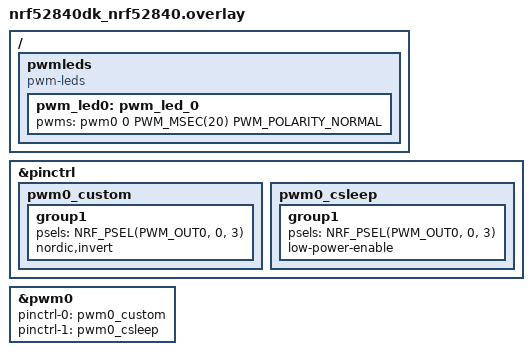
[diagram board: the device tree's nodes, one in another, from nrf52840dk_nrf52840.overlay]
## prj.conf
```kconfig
#Logging configurations
CONFIG_LOG=y
CONFIG_PWM_LOG_LEVEL_DBG=y
CONFIG_LOG_PRINTK=y
CONFIG_LOG_MODE_IMMEDIATE=y
CONFIG_STDOUT_CONSOLE=y
CONFIG_PRINTK=y

#PWM and LED configurations
CONFIG_PWM=y
CONFIG_LED=y
CONFIG_LED_PWM=y

# Step 3.1 - Config for button handler
# Configure buttons and LEDs. CONFIG_GPIO is already enabled through other configs?
CONFIG_DK_LIBRARY=y
```

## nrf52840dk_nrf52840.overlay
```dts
// To get started, press Ctrl+Space to bring up the completion menu and view the available nodes.

// You can also use the buttons in the sidebar to perform actions on nodes.
// Actions currently available include:

// * Enabling / disabling the node
// * Adding the bus to a bus
// * Removing the node
// * Connecting ADC channels

// For more help, browse the DeviceTree documentation at https://docs.zephyrproject.org/latest/guides/dts/index.html
// You can also visit the nRF DeviceTree extension documentation at https://nrfconnect.github.io/vscode-nrf-connect/devicetree/nrfdevicetree.html




/* Step 1.4 - Define pwm0_custom and pwm0_sleep */
&pinctrl {
    pwm0_custom: pwm0_custom {
        group1 {
            psels = <NRF_PSEL(PWM_OUT0, 0, 3)>;
            nordic,invert;
        };
    };

    pwm0_csleep: pwm0_csleep {
        group1 {
            psels = <NRF_PSEL(PWM_OUT0, 0, 3)>;
            low-power-enable;
        };
    };
};
/* Step 1.3 - Add the pwm0 instance */
&pwm0 {
    status = "okay";
    pinctrl-0 = <&pwm0_custom>;
    pinctrl-1 = <&pwm0_csleep>;
    pinctrl-names = "default", "sleep";
};

/* Step 1.2 -  Add a pwm_led instance and change the polarity */
/{
    pwmleds {
        compatible = "pwm-leds";
        pwm_led0: pwm_led_0 {
            pwms = <&pwm0 0 PWM_MSEC(20) PWM_POLARITY_NORMAL>;
        };
    };
};
```

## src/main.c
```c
#include <zephyr/kernel.h>
#include <zephyr/device.h>
#include <zephyr/drivers/pwm.h>
#include <zephyr/logging/log.h>
#include <dk_buttons_and_leds.h>

#define LOG_MODULE_NAME excersize_3
LOG_MODULE_REGISTER(LOG_MODULE_NAME);

static const struct pwm_dt_spec pwm_led0 = PWM_DT_SPEC_GET(DT_ALIAS(pwm_led0));


#define PWM_PERIOD_NS 10000000
#define PWM_DUTY_CYCLE 1400000

/* Step  2.2 - Define minimum and maximum duty cycle */
#define PWM_MIN_DUTY_CYCLE 600000
#define PWM_MAX_DUTY_CYCLE 2000000

/* Step 3 - Create an initializing function to verify that the device is enabled*/ 
int motor_init(void)
{
    int err = 0;
    LOG_INF("Initializing Motor Control");

    if (!device_is_ready(pwm_led0.dev)) {
    LOG_ERR("Error: PWM device %s is not ready",
            pwm_led0.dev->name);
    return -EBUSY;
	}

    err = pwm_set_dt(&pwm_led0, PWM_PERIOD_NS, PWM_DUTY_CYCLE);
    if (err) {
        LOG_ERR("pwm_set_dt returned %d", err);
    }

    return err;
}

/* Step 2.1 - Create a function to set the angle of the motor*/
int set_motor_angle(uint32_t duty_cycle_ns)
{
    int err;
    err = pwm_set_dt(&pwm_led0, PWM_PERIOD_NS, duty_cycle_ns);
    if (err) {
        LOG_ERR("pwm_set_dt_returned %d", err);
    }
 
    return err;
}

/* Step 3.4 - Add button handler callback function */
void button_handler(uint32_t button_state, uint32_t has_changed)
{
    int err = 0;
	int button_pressed = 0;
	if (has_changed & button_state)
	{
		switch (has_changed)
		{
			case DK_BTN1_MSK:
				button_pressed = 1;
                err = set_motor_angle(PWM_MIN_DUTY_CYCLE);
				break;
			case DK_BTN2_MSK:
				button_pressed = 2;
                err = set_motor_angle(PWM_MAX_DUTY_CYCLE);
				break;
			default:
				break;
		}
        LOG_INF("Button %d pressed.", button_pressed);
        if (err) {
            LOG_ERR("couldn't set duty cycle. Err %d", err);
        }
		LOG_INF("Button %d pressed.", button_pressed);
	}
}

/* Step 3.2 - Create a button and led initialization function */
static void configure_dk_buttons_and_leds(void)
{
    int err;

    err = dk_buttons_init(button_handler);
    if (err) {
        LOG_ERR("Couldn't init buttons (err %d)", err);
    }
}


void main(void)
{
    LOG_INF("Starting PWM basic sample \n");
    motor_init();
    /* Step 3.2 - Test your code */
    configure_dk_buttons_and_leds();

    for (;;){

        /* Step 2.3 */
        LOG_INF("Setting motor angle to %d",PWM_MIN_DUTY_CYCLE);
        set_motor_angle(PWM_MIN_DUTY_CYCLE);
        k_sleep(K_SECONDS(5));
        LOG_INF("Setting motor angle to %d",PWM_MAX_DUTY_CYCLE);
        set_motor_angle(PWM_MAX_DUTY_CYCLE);
        k_sleep(K_SECONDS(5));
    
    }
      
}
```
